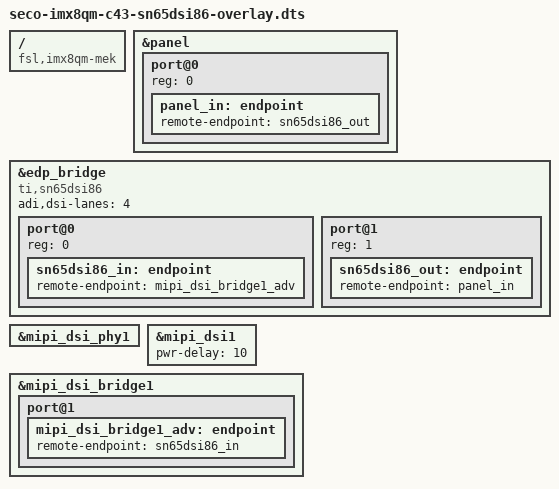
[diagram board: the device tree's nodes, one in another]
/*
 * Copyright 2017 NXP
 *
 * This program is free software; you can redistribute it and/or
 * modify it under the terms of the GNU General Public License
 * as published by the Free Software Foundation; either version 2
 * of the License, or (at your option) any later version.
 *
 * This program is distributed in the hope that it will be useful,
 * but WITHOUT ANY WARRANTY; without even the implied warranty of
 * MERCHANTABILITY or FITNESS FOR A PARTICULAR PURPOSE.  See the
 * GNU General Public License for more details.
 */

/dts-v1/;
/plugin/;

/ {
        compatible = "fsl,imx8qm-mek","fsl,seco-imx8qm-c43", "fsl,imx8qm";

/*  __________________________________________________________________________
 * |                                                                          |
 * |                               WiFi                                       |
 * |__________________________________________________________________________|
 */


	fragment@6 {
                target = <&panel>;
                __overlay__ {
                        status = "okay";
			#address-cells = <1>;
                        #size-cells = <0>;
			port@0 {
				reg = <0>;
                      		panel_in: endpoint {
					remote-endpoint = <&sn65dsi86_out>;
                      		};
			};

                 };
        };
	
	fragment@7 {
                target = <&edp_bridge>;
                __overlay__ {
                        compatible = "ti,sn65dsi86";
			adi,dsi-lanes = <4>;
	                #address-cells = <1>;
	                #size-cells = <0>;

			status = "okay";

			port@0 {
				reg = <0>;
				sn65dsi86_in: endpoint {
					remote-endpoint = <&mipi_dsi_bridge1_adv>;
				};
			};

			port@1 {
				reg = <1>;
				sn65dsi86_out: endpoint {
					remote-endpoint = <&panel_in>;
				};
			};

		};
	};
	
	fragment@8 {
                target = <&mipi_dsi_phy1>;
                __overlay__ {
                        status = "okay";
                 };
        };

	fragment@9 {
                target = <&mipi_dsi1>;
                __overlay__ {
			status = "okay";
			pwr-delay = <10>;

	//		port@1 {
	//			mipi_dsi_in: endpoint {
	//				remote-endpoint = <&dcss_disp0_mipi_dsi>;
	//			};
	//		}; 
		};
	};

	fragment@10 {
                target = <&mipi_dsi_bridge1>;
                __overlay__ {
                        status = "okay";
			port@1 {
				mipi_dsi_bridge1_adv: endpoint {
					remote-endpoint = <&sn65dsi86_in>;
				};
			};
		};
        };

};
